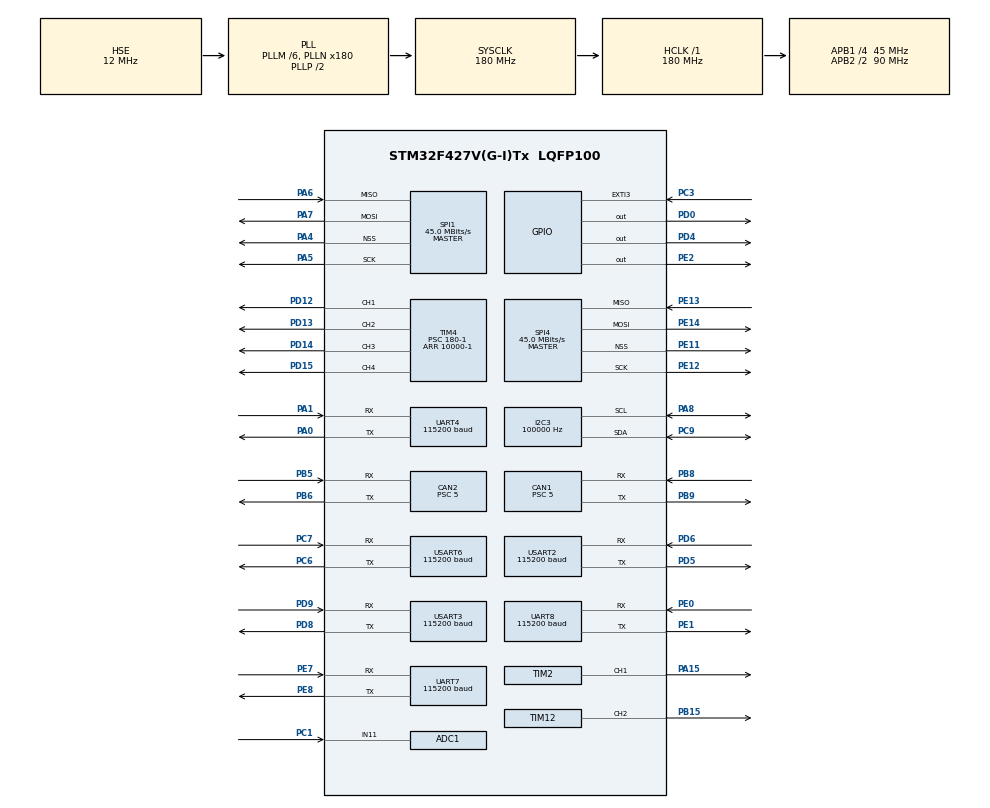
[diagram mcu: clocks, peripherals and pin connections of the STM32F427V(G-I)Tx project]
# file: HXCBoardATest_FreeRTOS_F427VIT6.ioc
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ADC1.Channel-0\#ChannelRegularConversion=ADC_CHANNEL_11
ADC1.Channel-IN11=ADC_CHANNEL_11
ADC1.ClockPrescaler=ADC_CLOCK_SYNC_PCLK_DIV4
ADC1.ContinuousConvMode=DISABLE
ADC1.DMAContinuousRequests=DISABLE
ADC1.DataAlign=ADC_DATAALIGN_RIGHT
ADC1.DiscontinuousConvMode=DISABLE
ADC1.EOCSelection=ADC_EOC_SINGLE_CONV
ADC1.EnableAnalogWatchDog=false
ADC1.ExternalTrigConv=ADC_SOFTWARE_START
ADC1.ExternalTrigConvEdge=ADC_EXTERNALTRIGCONVEDGE_NONE
ADC1.InjNumberOfConversion=0
ADC1.Mode=__NULL
ADC1.NbrOfConversion=1
ADC1.Rank-0\#ChannelRegularConversion=1
ADC1.Resolution=ADC_RESOLUTION_12B
ADC1.SamplingTime-0\#ChannelRegularConversion=ADC_SAMPLETIME_3CYCLES
ADC1.ScanConvMode=DISABLE
ADC1.master=1
CAN1.ABOM=DISABLE
CAN1.AWUM=DISABLE
CAN1.BS1=CAN_BS1_7TQ
CAN1.BS2=CAN_BS2_1TQ
CAN1.CalculateBaudRate=1000000
CAN1.CalculateTimeBit=1000
CAN1.CalculateTimeQuantum=111.11111111111111
CAN1.Mode=CAN_MODE_NORMAL
CAN1.NART=DISABLE
CAN1.Prescaler=5
CAN1.RFLM=DISABLE
CAN1.SJW=CAN_SJW_1TQ
CAN1.TTCM=DISABLE
CAN1.TXFP=DISABLE
CAN2.ABOM=DISABLE
CAN2.AWUM=DISABLE
CAN2.BS1=CAN_BS1_7TQ
CAN2.BS2=CAN_BS2_1TQ
CAN2.CalculateBaudRate=1000000
CAN2.CalculateTimeBit=1000
CAN2.CalculateTimeQuantum=111.11111111111111
CAN2.Mode=CAN_MODE_NORMAL
CAN2.NART=DISABLE
CAN2.Prescaler=5
CAN2.RFLM=DISABLE
CAN2.SJW=CAN_SJW_1TQ
CAN2.TTCM=DISABLE
CAN2.TXFP=DISABLE
Dma.Request0=USART2_RX
Dma.Request1=USART2_TX
Dma.Request2=USART6_RX
Dma.Request3=USART6_TX
Dma.Request4=UART4_RX
Dma.Request5=UART4_TX
Dma.Request6=UART7_TX
Dma.Request7=UART7_RX
Dma.UART4_RX.4.Direction=DMA_PERIPH_TO_MEMORY
Dma.UART4_RX.4.FIFOMode=DMA_FIFOMODE_DISABLE
Dma.UART4_RX.4.Instance=DMA1_Stream2
Dma.UART4_RX.4.MemDataAlignment=DMA_MDATAALIGN_BYTE
Dma.UART4_RX.4.MemInc=DMA_MINC_ENABLE
Dma.UART4_RX.4.Mode=DMA_CIRCULAR
Dma.UART4_RX.4.PeriphDataAlignment=DMA_PDATAALIGN_BYTE
Dma.UART4_RX.4.PeriphInc=DMA_PINC_DISABLE
Dma.UART4_RX.4.Priority=DMA_PRIORITY_LOW
Dma.UART4_TX.5.Direction=DMA_MEMORY_TO_PERIPH
Dma.UART4_TX.5.FIFOMode=DMA_FIFOMODE_DISABLE
Dma.UART4_TX.5.Instance=DMA1_Stream4
Dma.UART4_TX.5.MemDataAlignment=DMA_MDATAALIGN_BYTE
Dma.UART4_TX.5.MemInc=DMA_MINC_ENABLE
Dma.UART4_TX.5.Mode=DMA_NORMAL
Dma.UART4_TX.5.PeriphDataAlignment=DMA_PDATAALIGN_BYTE
Dma.UART4_TX.5.PeriphInc=DMA_PINC_DISABLE
Dma.UART4_TX.5.Priority=DMA_PRIORITY_LOW
Dma.UART7_RX.7.Direction=DMA_PERIPH_TO_MEMORY
Dma.UART7_RX.7.FIFOMode=DMA_FIFOMODE_DISABLE
Dma.UART7_RX.7.Instance=DMA1_Stream3
Dma.UART7_RX.7.MemDataAlignment=DMA_MDATAALIGN_BYTE
Dma.UART7_RX.7.MemInc=DMA_MINC_ENABLE
Dma.UART7_RX.7.Mode=DMA_CIRCULAR
Dma.UART7_RX.7.PeriphDataAlignment=DMA_PDATAALIGN_BYTE
Dma.UART7_RX.7.PeriphInc=DMA_PINC_DISABLE
Dma.UART7_RX.7.Priority=DMA_PRIORITY_LOW
Dma.UART7_TX.6.Direction=DMA_MEMORY_TO_PERIPH
Dma.UART7_TX.6.FIFOMode=DMA_FIFOMODE_DISABLE
Dma.UART7_TX.6.Instance=DMA1_Stream1
Dma.UART7_TX.6.MemDataAlignment=DMA_MDATAALIGN_BYTE
Dma.UART7_TX.6.MemInc=DMA_MINC_ENABLE
Dma.UART7_TX.6.Mode=DMA_NORMAL
Dma.UART7_TX.6.PeriphDataAlignment=DMA_PDATAALIGN_BYTE
Dma.UART7_TX.6.PeriphInc=DMA_PINC_DISABLE
Dma.UART7_TX.6.Priority=DMA_PRIORITY_LOW
Dma.USART2_RX.0.Direction=DMA_PERIPH_TO_MEMORY
Dma.USART2_RX.0.FIFOMode=DMA_FIFOMODE_DISABLE
Dma.USART2_RX.0.Instance=DMA1_Stream5
Dma.USART2_RX.0.MemDataAlignment=DMA_MDATAALIGN_BYTE
Dma.USART2_RX.0.MemInc=DMA_MINC_ENABLE
Dma.USART2_RX.0.Mode=DMA_CIRCULAR
Dma.USART2_RX.0.PeriphDataAlignment=DMA_PDATAALIGN_BYTE
Dma.USART2_RX.0.PeriphInc=DMA_PINC_DISABLE
Dma.USART2_RX.0.Priority=DMA_PRIORITY_LOW
Dma.USART2_TX.1.Direction=DMA_MEMORY_TO_PERIPH
Dma.USART2_TX.1.FIFOMode=DMA_FIFOMODE_DISABLE
Dma.USART2_TX.1.Instance=DMA1_Stream6
Dma.USART2_TX.1.MemDataAlignment=DMA_MDATAALIGN_BYTE
Dma.USART2_TX.1.MemInc=DMA_MINC_ENABLE
Dma.USART2_TX.1.Mode=DMA_NORMAL
Dma.USART2_TX.1.PeriphDataAlignment=DMA_PDATAALIGN_BYTE
Dma.USART2_TX.1.PeriphInc=DMA_PINC_DISABLE
Dma.USART2_TX.1.Priority=DMA_PRIORITY_LOW
Dma.USART6_RX.2.Direction=DMA_PERIPH_TO_MEMORY
Dma.USART6_RX.2.FIFOMode=DMA_FIFOMODE_DISABLE
Dma.USART6_RX.2.Instance=DMA2_Stream1
Dma.USART6_RX.2.MemDataAlignment=DMA_MDATAALIGN_BYTE
Dma.USART6_RX.2.MemInc=DMA_MINC_ENABLE
Dma.USART6_RX.2.Mode=DMA_CIRCULAR
Dma.USART6_RX.2.PeriphDataAlignment=DMA_PDATAALIGN_BYTE
Dma.USART6_RX.2.PeriphInc=DMA_PINC_DISABLE
Dma.USART6_RX.2.Priority=DMA_PRIORITY_LOW
Dma.USART6_TX.3.Direction=DMA_MEMORY_TO_PERIPH
Dma.USART6_TX.3.FIFOMode=DMA_FIFOMODE_DISABLE
Dma.USART6_TX.3.Instance=DMA2_Stream6
Dma.USART6_TX.3.MemDataAlignment=DMA_MDATAALIGN_BYTE
Dma.USART6_TX.3.MemInc=DMA_MINC_ENABLE
Dma.USART6_TX.3.Mode=DMA_NORMAL
Dma.USART6_TX.3.PeriphDataAlignment=DMA_PDATAALIGN_BYTE
Dma.USART6_TX.3.PeriphInc=DMA_PINC_DISABLE
Dma.USART6_TX.3.Priority=DMA_PRIORITY_LOW
FREERTOS.Tasks01=defaultTask,24,1024,StartDefaultTask,Default,NULL,Dynamic,NULL,NULL
FREERTOS.configENABLE_FPU=1
FREERTOS.configTOTAL_HEAP_SIZE=49152
I2C3.AddressingMode=I2C_ADDRESSINGMODE_7BIT
I2C3.Analog_Filter=I2C_ANALOGFILTER_ENABLE
I2C3.ClockSpeed=100000
I2C3.DualAddressMode=I2C_DUALADDRESS_DISABLE
I2C3.GeneralCallMode=I2C_GENERALCALL_DISABLE
I2C3.I2C_Coeff_DF=0
I2C3.I2C_Mode=I2C_Standard
I2C3.NoStretchMode=I2C_NOSTRETCH_DISABLE
I2C3.OwnAddress=0
Mcu.Family=STM32F4
Mcu.Name=STM32F427V(G-I)Tx
Mcu.Package=LQFP100
NVIC.CAN1_RX0_IRQn=true\:5\:0\:false\:false\:true\:true\:true\:true\:true
NVIC.CAN1_RX1_IRQn=true\:5\:0\:false\:false\:true\:true\:true\:true\:true
NVIC.CAN1_SCE_IRQn=true\:5\:0\:false\:false\:true\:true\:true\:true\:true
NVIC.CAN1_TX_IRQn=true\:5\:0\:false\:false\:true\:true\:true\:true\:true
NVIC.CAN2_RX0_IRQn=true\:5\:0\:false\:false\:true\:true\:true\:true\:true
NVIC.CAN2_RX1_IRQn=true\:5\:0\:false\:false\:true\:true\:true\:true\:true
NVIC.CAN2_SCE_IRQn=true\:5\:0\:false\:false\:true\:true\:true\:true\:true
NVIC.CAN2_TX_IRQn=true\:5\:0\:false\:false\:true\:true\:true\:true\:true
NVIC.DMA1_Stream1_IRQn=true\:5\:0\:false\:false\:true\:true\:false\:true\:true
NVIC.DMA1_Stream2_IRQn=true\:5\:0\:false\:false\:true\:true\:false\:true\:true
NVIC.DMA1_Stream3_IRQn=true\:5\:0\:false\:false\:true\:true\:false\:true\:true
NVIC.DMA1_Stream4_IRQn=true\:5\:0\:false\:false\:true\:true\:false\:true\:true
NVIC.DMA1_Stream5_IRQn=true\:5\:0\:false\:false\:true\:true\:false\:true\:true
NVIC.DMA1_Stream6_IRQn=true\:5\:0\:false\:false\:true\:true\:false\:true\:true
NVIC.DMA2_Stream1_IRQn=true\:5\:0\:false\:false\:true\:true\:false\:true\:true
NVIC.DMA2_Stream6_IRQn=true\:5\:0\:false\:false\:true\:true\:false\:true\:true
NVIC.PriorityGroup=NVIC_PRIORITYGROUP_4
NVIC.TIM1_BRK_TIM9_IRQn=true\:5\:0\:false\:false\:true\:true\:true\:true\:true
NVIC.TIM6_DAC_IRQn=true\:5\:0\:false\:false\:true\:true\:true\:true\:true
NVIC.TIM7_IRQn=true\:5\:0\:false\:false\:true\:true\:true\:true\:true
NVIC.TIM8_TRG_COM_TIM14_IRQn=true\:5\:0\:false\:false\:true\:false\:false\:true\:true
NVIC.TimeBase=TIM8_TRG_COM_TIM14_IRQn
NVIC.TimeBaseIP=TIM14
NVIC.UART4_IRQn=true\:5\:0\:false\:false\:true\:true\:true\:true\:true
NVIC.UART7_IRQn=true\:5\:0\:false\:false\:true\:true\:true\:true\:true
NVIC.USART2_IRQn=true\:5\:0\:false\:false\:true\:true\:true\:true\:true
NVIC.USART6_IRQn=true\:5\:0\:false\:false\:true\:true\:true\:true\:true
PA0/WKUP.Mode=Asynchronous
PA0/WKUP.Signal=UART4_TX
PA1.Mode=Asynchronous
PA1.Signal=UART4_RX
PA13.Mode=Serial_Wire
PA13.Signal=SYS_JTMS-SWDIO
PA14.Mode=Serial_Wire
PA14.Signal=SYS_JTCK-SWCLK
PA15.Signal=S_TIM2_CH1_ETR
PA4.Mode=NSS_Signal_Hard_Output
PA4.Signal=SPI1_NSS
PA5.Mode=Full_Duplex_Master
PA5.Signal=SPI1_SCK
PA6.Mode=Full_Duplex_Master
PA6.Signal=SPI1_MISO
PA7.Mode=Full_Duplex_Master
PA7.Signal=SPI1_MOSI
PA8.Mode=I2C
PA8.Signal=I2C3_SCL
PB15.Signal=S_TIM12_CH2
PB5.Mode=CAN_Activate
PB5.Signal=CAN2_RX
PB6.Mode=CAN_Activate
PB6.Signal=CAN2_TX
PB8.Mode=CAN_Activate
PB8.Signal=CAN1_RX
PB9.Mode=CAN_Activate
PB9.Signal=CAN1_TX
PC1.Signal=ADCx_IN11
PC3.Signal=GPXTI3
PC6.Mode=Asynchronous
PC6.Signal=USART6_TX
PC7.Mode=Asynchronous
PC7.Signal=USART6_RX
PC9.Mode=I2C
PC9.Signal=I2C3_SDA
PD0.Signal=GPIO_Output
PD12.Signal=S_TIM4_CH1
PD13.Signal=S_TIM4_CH2
PD14.Signal=S_TIM4_CH3
PD15.Signal=S_TIM4_CH4
PD4.Signal=GPIO_Output
PD5.Mode=Asynchronous
PD5.Signal=USART2_TX
PD6.Mode=Asynchronous
PD6.Signal=USART2_RX
PD8.Mode=Asynchronous
PD8.Signal=USART3_TX
PD9.Mode=Asynchronous
PD9.Signal=USART3_RX
PE0.Mode=Asynchronous
PE0.Signal=UART8_RX
PE1.Mode=Asynchronous
PE1.Signal=UART8_TX
PE11.Mode=NSS_Signal_Hard_Output
PE11.Signal=SPI4_NSS
PE12.Mode=Full_Duplex_Master
PE12.Signal=SPI4_SCK
PE13.Mode=Full_Duplex_Master
PE13.Signal=SPI4_MISO
PE14.Mode=Full_Duplex_Master
PE14.Signal=SPI4_MOSI
PE2.Signal=GPIO_Output
PE7.Mode=Asynchronous
PE7.Signal=UART7_RX
PE8.Mode=Asynchronous
PE8.Signal=UART7_TX
PH0/OSC_IN.Mode=HSE-External-Oscillator
PH0/OSC_IN.Signal=RCC_OSC_IN
PH1/OSC_OUT.Mode=HSE-External-Oscillator
PH1/OSC_OUT.Signal=RCC_OSC_OUT
ProjectManager.HeapSize=0x400
ProjectManager.StackSize=0x1000
ProjectManager.TargetToolchain=MDK-ARM V5.32
RCC.48MHZClocksFreq_Value=90000000
RCC.AHBFreq_Value=180000000
RCC.APB1CLKDivider=RCC_HCLK_DIV4
RCC.APB1Freq_Value=45000000
RCC.APB1TimFreq_Value=90000000
RCC.APB2CLKDivider=RCC_HCLK_DIV2
RCC.APB2Freq_Value=90000000
RCC.APB2TimFreq_Value=180000000
RCC.CortexFreq_Value=180000000
RCC.EnbaleCSS=true
RCC.HCLKFreq_Value=180000000
RCC.HSE_VALUE=12000000
RCC.HSI_VALUE=16000000
RCC.LSE_VALUE=32768
RCC.PLLM=6
RCC.PLLN=180
RCC.PLLSourceVirtual=RCC_PLLSOURCE_HSE
RCC.SYSCLKFreq_VALUE=180000000
RCC.SYSCLKSource=RCC_SYSCLKSOURCE_PLLCLK
RCC.VCOOutputFreq_Value=360000000
SH.ADCx_IN11.0=ADC1_IN11,IN11
SH.S_TIM12_CH2.0=TIM12_CH2,PWM Generation2 CH2
SH.S_TIM2_CH1_ETR.0=TIM2_CH1,PWM Generation1 CH1
SH.S_TIM4_CH1.0=TIM4_CH1,PWM Generation1 CH1
SH.S_TIM4_CH2.0=TIM4_CH2,PWM Generation2 CH2
SH.S_TIM4_CH3.0=TIM4_CH3,PWM Generation3 CH3
SH.S_TIM4_CH4.0=TIM4_CH4,PWM Generation4 CH4
SPI1.BaudRatePrescaler=SPI_BAUDRATEPRESCALER_2
SPI1.CLKPhase=SPI_PHASE_1EDGE
SPI1.CLKPolarity=SPI_POLARITY_LOW
SPI1.CRCCalculation=SPI_CRCCALCULATION_DISABLE
SPI1.CalculateBaudRate=45.0 MBits/s
SPI1.DataSize=SPI_DATASIZE_8BIT
SPI1.Direction=SPI_DIRECTION_2LINES
SPI1.FirstBit=SPI_FIRSTBIT_MSB
SPI1.Mode=SPI_MODE_MASTER
SPI1.NSS=SPI_NSS_HARD_OUTPUT
SPI1.TIMode=SPI_TIMODE_DISABLE
SPI1.VirtualNSS=VM_NSSHARD
SPI1.VirtualType=VM_MASTER
SPI4.BaudRatePrescaler=SPI_BAUDRATEPRESCALER_2
SPI4.CLKPhase=SPI_PHASE_1EDGE
SPI4.CLKPolarity=SPI_POLARITY_LOW
SPI4.CRCCalculation=SPI_CRCCALCULATION_DISABLE
SPI4.CalculateBaudRate=45.0 MBits/s
SPI4.DataSize=SPI_DATASIZE_8BIT
SPI4.Direction=SPI_DIRECTION_2LINES
SPI4.FirstBit=SPI_FIRSTBIT_MSB
SPI4.Mode=SPI_MODE_MASTER
SPI4.NSS=SPI_NSS_HARD_OUTPUT
SPI4.TIMode=SPI_TIMODE_DISABLE
SPI4.VirtualNSS=VM_NSSHARD
SPI4.VirtualType=VM_MASTER
STMicroelectronics.X-CUBE-ALGOBUILD.1.4.0.LibraryCcDSPOoLibraryJjDSPOoLibrary=true
TIM12.AutoReloadPreload=TIM_AUTORELOAD_PRELOAD_DISABLE
TIM12.Channel-PWM\ Generation2\ CH2=TIM_CHANNEL_2
TIM12.ClockDivision=TIM_CLOCKDIVISION_DIV1
TIM12.CounterMode=TIM_COUNTERMODE_UP
TIM12.OC2Preload_PWM=ENABLE
TIM12.OCFastMode_PWM-PWM\ Generation2\ CH2=TIM_OCFAST_DISABLE
TIM12.OCMode_PWM-PWM\ Generation2\ CH2=TIM_OCMODE_PWM1
TIM12.OCPolarity_2=TIM_OCPOLARITY_HIGH
TIM12.Period=65535
TIM12.Prescaler=0
TIM12.Pulse-PWM\ Generation2\ CH2=0
TIM2.AutoReloadPreload=TIM_AUTORELOAD_PRELOAD_DISABLE
TIM2.Channel-PWM\ Generation1\ CH1=TIM_CHANNEL_1
TIM2.ClockDivision=TIM_CLOCKDIVISION_DIV1
TIM2.CounterMode=TIM_COUNTERMODE_UP
TIM2.OC1Preload_PWM=ENABLE
TIM2.OCFastMode_PWM-PWM\ Generation1\ CH1=TIM_OCFAST_DISABLE
TIM2.OCMode_PWM-PWM\ Generation1\ CH1=TIM_OCMODE_PWM1
TIM2.OCPolarity_1=TIM_OCPOLARITY_HIGH
TIM2.Period=4294967295
TIM2.Prescaler=0
TIM2.Pulse-PWM\ Generation1\ CH1=0
TIM2.TIM_MasterOutputTrigger=TIM_TRGO_RESET
TIM2.TIM_MasterSlaveMode=TIM_MASTERSLAVEMODE_DISABLE
TIM4.Channel-PWM\ Generation1\ CH1=TIM_CHANNEL_1
TIM4.Channel-PWM\ Generation2\ CH2=TIM_CHANNEL_2
TIM4.Channel-PWM\ Generation3\ CH3=TIM_CHANNEL_3
TIM4.Channel-PWM\ Generation4\ CH4=TIM_CHANNEL_4
TIM4.Period=10000-1
TIM4.Prescaler=180-1
TIM6.AutoReloadPreload=TIM_AUTORELOAD_PRELOAD_ENABLE
TIM7.AutoReloadPreload=TIM_AUTORELOAD_PRELOAD_ENABLE
UART4.BaudRate=115200
UART4.Mode=MODE_TX_RX
UART4.OverSampling=UART_OVERSAMPLING_16
UART4.Parity=PARITY_NONE
UART4.StopBits=UART_STOPBITS_1
UART4.VirtualMode=Asynchronous
UART4.WordLength=WORDLENGTH_8B
UART7.BaudRate=115200
UART7.Mode=MODE_TX_RX
UART7.OverSampling=UART_OVERSAMPLING_16
UART7.Parity=PARITY_NONE
UART7.StopBits=UART_STOPBITS_1
UART7.VirtualMode=Asynchronous
UART7.WordLength=WORDLENGTH_8B
UART8.BaudRate=115200
UART8.Mode=MODE_TX_RX
UART8.OverSampling=UART_OVERSAMPLING_16
UART8.Parity=PARITY_NONE
UART8.StopBits=UART_STOPBITS_1
UART8.VirtualMode=Asynchronous
UART8.WordLength=WORDLENGTH_8B
USART2.BaudRate=115200
USART2.Mode=MODE_TX_RX
USART2.OverSampling=UART_OVERSAMPLING_16
USART2.Parity=PARITY_NONE
USART2.StopBits=STOPBITS_1
USART2.VirtualMode=VM_ASYNC
USART2.WordLength=WORDLENGTH_8B
USART3.BaudRate=115200
USART3.Mode=MODE_TX_RX
USART3.OverSampling=UART_OVERSAMPLING_16
USART3.Parity=PARITY_NONE
USART3.StopBits=STOPBITS_1
USART3.VirtualMode=VM_ASYNC
USART3.WordLength=WORDLENGTH_8B
USART6.BaudRate=115200
USART6.Mode=MODE_TX_RX
USART6.OverSampling=UART_OVERSAMPLING_16
USART6.Parity=PARITY_NONE
USART6.StopBits=STOPBITS_1
USART6.VirtualMode=VM_ASYNC
USART6.WordLength=WORDLENGTH_8B
VP_FREERTOS_VS_CMSIS_V2.Mode=CMSIS_V2
VP_STMicroelectronics.X-CUBE-ALGOBUILD_VS_DSPOoLibraryJjLibrary_1.4.0_1.4.0.Mode=DSPOoLibraryJjLibrary
VP_SYS_VS_tim14.Mode=TIM14
VP_TIM4_VS_ClockSourceINT.Mode=Internal
VP_TIM6_VS_ClockSourceINT.Mode=Enable_Timer
VP_TIM7_VS_ClockSourceINT.Mode=Enable_Timer
VP_TIM9_VS_ClockSourceINT.Mode=Internal
board=custom

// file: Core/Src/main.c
/* USER CODE BEGIN Header */
/**
  ******************************************************************************
  * @file           : main.c
  * @brief          : Main program body
  ******************************************************************************
  * @attention
  *
  * Copyright (c) 2025 STMicroelectronics.
  * All rights reserved.
  *
  * This software is licensed under terms that can be found in the LICENSE file
  * in the root directory of this software component.
  * If no LICENSE file comes with this software, it is provided AS-IS.
  *
  ******************************************************************************
  */
/* USER CODE END Header */
#include "main.h"
#include "cmsis_os.h"
#include "adc.h"
#include "can.h"
#include "dma.h"
#include "i2c.h"
#include "spi.h"
#include "tim.h"
#include "usart.h"
#include "gpio.h"

/* USER CODE BEGIN Includes */
#include "common_inc.h"
#include "BspTimer.h"
#include "BspDevice.h"
/* USER CODE END Includes */

void SystemClock_Config(void);
void MX_FREERTOS_Init(void);

int main(void)
{

  /* MCU Configuration--------------------------------------------------------*/

  /* Reset of all peripherals, Initializes the Flash interface and the Systick. */
  HAL_Init();

  /* Configure the system clock */
  SystemClock_Config();

  /* Initialize all configured peripherals */
  MX_GPIO_Init();
  MX_DMA_Init();
  MX_ADC1_Init();
  MX_CAN1_Init();
  MX_CAN2_Init();
  MX_I2C3_Init();
  MX_SPI1_Init();
  MX_SPI4_Init();
  MX_TIM2_Init();
  MX_TIM12_Init();
  MX_UART4_Init();
  MX_UART7_Init();
  MX_UART8_Init();
  MX_USART2_UART_Init();
  MX_USART3_UART_Init();
  MX_USART6_UART_Init();
  MX_TIM6_Init();
  MX_TIM4_Init();
  MX_TIM7_Init();
  MX_TIM9_Init();

  /* Init scheduler */
  osKernelInitialize();  /* Call init function for freertos objects (in cmsis_os2.c) */
  MX_FREERTOS_Init();

  /* Start scheduler */
  osKernelStart();

  /* We should never get here as control is now taken by the scheduler */

  /* Infinite loop */
  while (1)
  {

  }
}

void SystemClock_Config(void)
{
  RCC_OscInitTypeDef RCC_OscInitStruct = {0};
  RCC_ClkInitTypeDef RCC_ClkInitStruct = {0};

  /** Configure the main internal regulator output voltage
  */
  __HAL_RCC_PWR_CLK_ENABLE();
  __HAL_PWR_VOLTAGESCALING_CONFIG(PWR_REGULATOR_VOLTAGE_SCALE1);

  /** Initializes the RCC Oscillators according to the specified parameters
  * in the RCC_OscInitTypeDef structure.
  */
  RCC_OscInitStruct.OscillatorType = RCC_OSCILLATORTYPE_HSE;
  RCC_OscInitStruct.HSEState = RCC_HSE_ON;
  RCC_OscInitStruct.PLL.PLLState = RCC_PLL_ON;
  RCC_OscInitStruct.PLL.PLLSource = RCC_PLLSOURCE_HSE;
  RCC_OscInitStruct.PLL.PLLM = 6;
  RCC_OscInitStruct.PLL.PLLN = 180;
  RCC_OscInitStruct.PLL.PLLP = RCC_PLLP_DIV2;
  RCC_OscInitStruct.PLL.PLLQ = 4;
  if (HAL_RCC_OscConfig(&RCC_OscInitStruct) != HAL_OK)
  {
    Error_Handler();
  }

  /** Activate the Over-Drive mode
  */
  if (HAL_PWREx_EnableOverDrive() != HAL_OK)
  {
    Error_Handler();
  }

  /** Initializes the CPU, AHB and APB buses clocks
  */
  RCC_ClkInitStruct.ClockType = RCC_CLOCKTYPE_HCLK|RCC_CLOCKTYPE_SYSCLK
                              |RCC_CLOCKTYPE_PCLK1|RCC_CLOCKTYPE_PCLK2;
  RCC_ClkInitStruct.SYSCLKSource = RCC_SYSCLKSOURCE_PLLCLK;
  RCC_ClkInitStruct.AHBCLKDivider = RCC_SYSCLK_DIV1;
  RCC_ClkInitStruct.APB1CLKDivider = RCC_HCLK_DIV4;
  RCC_ClkInitStruct.APB2CLKDivider = RCC_HCLK_DIV2;

  if (HAL_RCC_ClockConfig(&RCC_ClkInitStruct, FLASH_LATENCY_5) != HAL_OK)
  {
    Error_Handler();
  }

  /** Enables the Clock Security System
  */
  HAL_RCC_EnableCSS();
}

void HAL_TIM_PeriodElapsedCallback(TIM_HandleTypeDef *htim)
{
  if (htim->Instance == TIM14)
  {
    HAL_IncTick();
  }
  /* USER CODE BEGIN Callback 1 */
  Timer_Callback_Trampoline(htim);
  /* USER CODE END Callback 1 */
}

void Error_Handler(void)
{
  __disable_irq();
  while (1)
  {
  }
}

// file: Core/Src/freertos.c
/* USER CODE BEGIN Header */
/**
  ******************************************************************************
  * File Name          : freertos.c
  * Description        : Code for freertos applications
  ******************************************************************************
  * @attention
  *
  * Copyright (c) 2025 STMicroelectronics.
  * All rights reserved.
  *
  * This software is licensed under terms that can be found in the LICENSE file
  * in the root directory of this software component.
  * If no LICENSE file comes with this software, it is provided AS-IS.
  *
  ******************************************************************************
  */
/* USER CODE END Header */

#include "FreeRTOS.h"
#include "task.h"
#include "main.h"
#include "cmsis_os.h"

/* USER CODE BEGIN Includes */
#include "UserMain.h"
/* USER CODE END Includes */

/* Definitions for defaultTask */
osThreadId_t defaultTaskHandle;
const osThreadAttr_t defaultTask_attributes = {
  .name = "defaultTask",
  .stack_size = 1024 * 4,
  .priority = (osPriority_t) osPriorityNormal,
};

void StartDefaultTask(void *argument);

void MX_FREERTOS_Init(void); /* (MISRA C 2004 rule 8.1) */

void MX_FREERTOS_Init(void) {

  /* Create the thread(s) */
  /* creation of defaultTask */
  defaultTaskHandle = osThreadNew(StartDefaultTask, NULL, &defaultTask_attributes);

}

void StartDefaultTask(void *argument)
{
  /* USER CODE BEGIN StartDefaultTask */
  userMain(); // 调用 C++ 入口点

  vTaskDelete(defaultTaskHandle); // 删除当前任务
  /* USER CODE END StartDefaultTask */
}
